# nrf5340_network register map
Vendor: Nordic Semiconductor; Series: nrf53; File version: 1
CPU: CM33 r0p4, little endian, MPU, no FPU, 3 interrupt priority bits, 30 interrupts
Registers are 32-bit, read-write, reset 0x0 unless marked. A register's access mark holds for its fields unless they carry their own. Offsets are from the block's base; [hi:lo] are bit positions; lines under a group give offsets from that group; {n}, {i} and the like mark numbered series.

## EGU0_NS — Event generator unit
Base 0x41014000
{0x0+4i} TASKS_TRIGGER[{i}] (i=0..15) wo — Description collection: Trigger n for triggering the corresponding TRIGGERED[n] event
  [0] TASKS_TRIGGER — Trigger n for triggering the corresponding TRIGGERED[n] event
    1=Trigger task
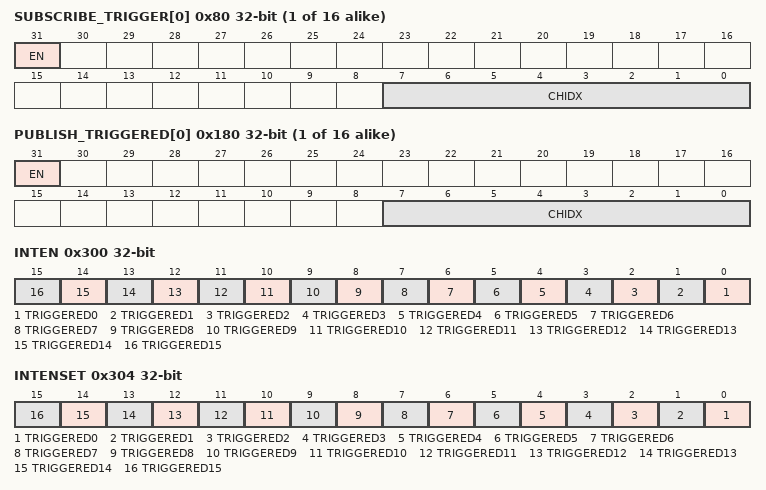
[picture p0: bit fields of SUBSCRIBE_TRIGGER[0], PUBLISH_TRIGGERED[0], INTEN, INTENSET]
{0x80+4i} SUBSCRIBE_TRIGGER[{i}] (i=0..15) — Description collection: Subscribe configuration for task TRIGGER[n]
  [31] EN
    0=Disabled (Disable subscription); 1=Enabled (Enable subscription)
  [7:0] CHIDX — DPPI channel that task TRIGGER[n] will subscribe to
{0x100+4i} EVENTS_TRIGGERED[{i}] (i=0..15) — Description collection: Event number n generated by triggering the corresponding TRIGGER[n] task
  [0] EVENTS_TRIGGERED — Event number n generated by triggering the corresponding TRIGGER[n] task
    0=NotGenerated (Event not generated); 1=Generated (Event generated)
{0x180+4i} PUBLISH_TRIGGERED[{i}] (i=0..15) — Description collection: Publish configuration for event TRIGGERED[n]
  [31] EN
    0=Disabled (Disable publishing); 1=Enabled (Enable publishing)
  [7:0] CHIDX — DPPI channel that event TRIGGERED[n] will publish to.
0x300 INTEN — Enable or disable interrupt
  [all] fields
    0=Disabled; 1=Enabled
  [n] TRIGGERED{n} (n=0..15) — Enable or disable interrupt for event TRIGGERED[{n}]
0x304 INTENSET — Enable interrupt
  [all] fields
    on read: 0=Disabled (Read: Disabled); 1=Enabled (Read: Enabled) | on write: 1=Set (Enable)
  [n] TRIGGERED{n} (n=0..15) — Write '1' to enable interrupt for event TRIGGERED[{n}]
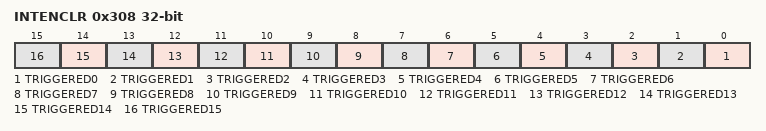
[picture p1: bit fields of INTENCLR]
0x308 INTENCLR — Disable interrupt
  [all] fields
    on read: 0=Disabled (Read: Disabled); 1=Enabled (Read: Enabled) | on write: 1=Clear (Disable)
  [n] TRIGGERED{n} (n=0..15) — Write '1' to disable interrupt for event TRIGGERED[{n}]

## SWI0_NS — Software interrupt 0
Base 0x4101A000
Same registers: SWI1_NS 0x4101B000, SWI2_NS 0x4101C000, SWI3_NS 0x4101D000

## APPMUTEX_NS — MUTEX 0
Base 0x40030000
Same registers: APPMUTEX_S 0x50030000
{0x400+4i} MUTEX[{i}] (i=0..15) — Description collection: Mutex register
  [0] MUTEX — Mutex register n
    0=Unlocked (Mutex n is in unlocked state); 1=Locked (Mutex n is in locked state)

## ACL_NS — Access control lists
Base 0x41080000
{0x800+0x10*i} ACL[{i}] (i=0..7) group — Unspecified
  0x00 ADDR rw-once — Description cluster: Start address of region to protect. The start address must be word-aligned.
    [31:0] ADDR — Start address of flash region n. The start address must point to a flash page boundary.
  0x04 SIZE rw-once — Description cluster: Size of region to protect counting from address ACL[n].ADDR. Writing a '0' has no effect.
    [31:0] SIZE — Size of flash region n in bytes. Must be a multiple of the flash page size.
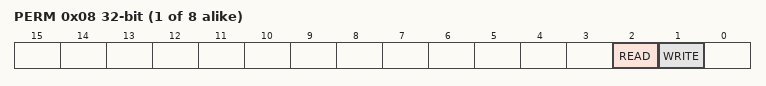
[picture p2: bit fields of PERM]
  0x08 PERM rw-once — Description cluster: Access permissions for region n as defined by start address ACL[n].ADDR and size ACL[n].SIZE
    [2] READ — Configure read permissions for region n. Writing a '0' has no effect.
      0=Enable (Allow read instructions to region n.); 1=Disable (Block read instructions to region n.)
    [1] WRITE — Configure write and erase permissions for region n. Writing a '0' has no effect.
      0=Enable (Allow write and erase instructions to region n.); 1=Disable (Block write and erase instructions to region n.)

## NVMC_NS — Non-volatile memory controller
Base 0x41080000; alternate view of ACL_NS
0x400 READY ro reset 0x1 — Ready flag
  [0] READY — NVMC is ready or busy
    0=Busy (NVMC is busy (ongoing write or erase operation)); 1=Ready (NVMC is ready)
0x408 READYNEXT ro reset 0x1 — Ready flag
  [0] READYNEXT — NVMC can accept a new write operation
    0=Busy (NVMC cannot accept any write operation); 1=Ready (NVMC is ready)
0x504 CONFIG — Configuration register
  [2:0] WEN — Program memory access mode. It is strongly recommended to only activate erase and write modes when they are actively used. Enabling write or erase will invalidate the cache and keep it invalidated.
    0=Ren (Read only access); 1=Wen (Write enabled); 2=Een (Erase enabled); 4=PEen (Partial erase enabled)
0x50C ERASEALL wo — Register for erasing all non-volatile user memory
  [0] ERASEALL — Erase all non-volatile memory including UICR registers. Before the non-volatile memory can be erased, erasing must be enabled by setting CONFIG.WEN=Een.
    0=NoOperation; 1=Erase (Start chip erase)
0x51C ERASEPAGEPARTIALCFG reset 0xA — Register for partial erase configuration
  [6:0] DURATION — Duration of the partial erase in milliseconds
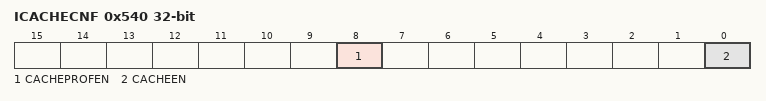
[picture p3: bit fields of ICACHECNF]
0x540 ICACHECNF — I-code cache configuration register
  [8] CACHEPROFEN — Cache profiling enable
    0=Disabled (Disable cache profiling); 1=Enabled (Enable cache profiling)
  [0] CACHEEN — Cache enable
    0=Disabled (Disable cache. Invalidates all cache entries.); 1=Enabled (Enable cache)
0x548 IHIT — I-code cache hit counter
  [31:0] HITS — Number of cache hits Write zero to clear
0x54C IMISS — I-code cache miss counter
  [31:0] MISSES — Number of cache misses Write zero to clear

## VMC_NS — Volatile Memory controller
Base 0x41081000
{0x600+0x10*i} RAM[{i}] (i=0..3) group — Unspecified
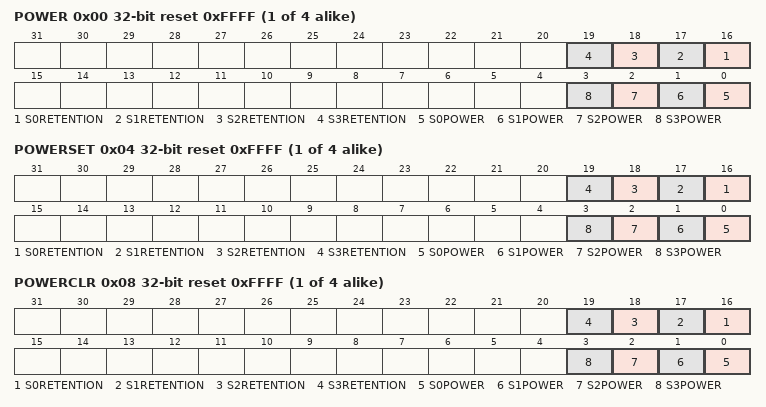
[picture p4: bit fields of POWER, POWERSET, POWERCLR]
  0x00 POWER reset 0xFFFF — Description cluster: RAM[n] power control register
    [all] fields
      0=Off; 1=On
    [n+16] S{n}RETENTION (n=0..3) — Keep retention on RAM section S{n} of RAM[n] when RAM section is switched off
    [n] S{n}POWER (n=0..3) — Keep RAM section S{n} of RAM[n] on or off in System ON mode
  0x04 POWERSET reset 0xFFFF — Description cluster: RAM[n] power control set register
    [all] fields
      1=On
    [n+16] S{n}RETENTION (n=0..3) — Keep retention on RAM section S{n} of RAM[n] when RAM section is switched off
    [n] S{n}POWER (n=0..3) — Keep RAM section S{n} of RAM[n] on or off in System ON mode
  0x08 POWERCLR reset 0xFFFF — Description cluster: RAM[n] power control clear register
    [all] fields
      1=Off
    [n+16] S{n}RETENTION (n=0..3) — Keep retention on RAM section S{n} of RAM[n] when RAM section is switched off
    [n] S{n}POWER (n=0..3) — Keep RAM section S{n} of RAM[n] on or off in System ON mode

## Notices in the file
Copyright (c) 2010 - 2024, Nordic Semiconductor ASA All rights reserved.
SPDX-License-Identifier: BSD-3-Clause
Redistribution and use in source and binary forms, with or without
modification, are permitted provided that the following conditions are met:
1. Redistributions of source code must retain the above copyright notice, this
list of conditions and the following disclaimer.
2. Redistributions in binary form must reproduce the above copyright
notice, this list of conditions and the following disclaimer in the
documentation and/or other materials provided with the distribution.
3. Neither the name of Nordic Semiconductor ASA nor the names of its
contributors may be used to endorse or promote products derived from this
software without specific prior written permission.
THIS SOFTWARE IS PROVIDED BY THE COPYRIGHT HOLDERS AND CONTRIBUTORS "AS IS"
AND ANY EXPRESS OR IMPLIED WARRANTIES, INCLUDING, BUT NOT LIMITED TO, THE
IMPLIED WARRANTIES OF MERCHANTABILITY, AND FITNESS FOR A PARTICULAR PURPOSE
ARE DISCLAIMED. IN NO EVENT SHALL NORDIC SEMICONDUCTOR ASA OR CONTRIBUTORS BE
LIABLE FOR ANY DIRECT, INDIRECT, INCIDENTAL, SPECIAL, EXEMPLARY, OR
CONSEQUENTIAL DAMAGES (INCLUDING, BUT NOT LIMITED TO, PROCUREMENT OF
SUBSTITUTE GOODS OR SERVICES; LOSS OF USE, DATA, OR PROFITS; OR BUSINESS
INTERRUPTION) HOWEVER CAUSED AND ON ANY THEORY OF LIABILITY, WHETHER IN
CONTRACT, STRICT LIABILITY, OR TORT (INCLUDING NEGLIGENCE OR OTHERWISE)
ARISING IN ANY WAY OUT OF THE USE OF THIS SOFTWARE, EVEN IF ADVISED OF THE
POSSIBILITY OF SUCH DAMAGE.
